# ATSAMC21N17A register map
Registers are 32-bit, access not given, no defined reset value unless marked. A register's access mark holds for its fields unless they carry their own. Addresses are absolute; registers are grouped by the start of their names; [hi:lo] are bit positions.

## TC1
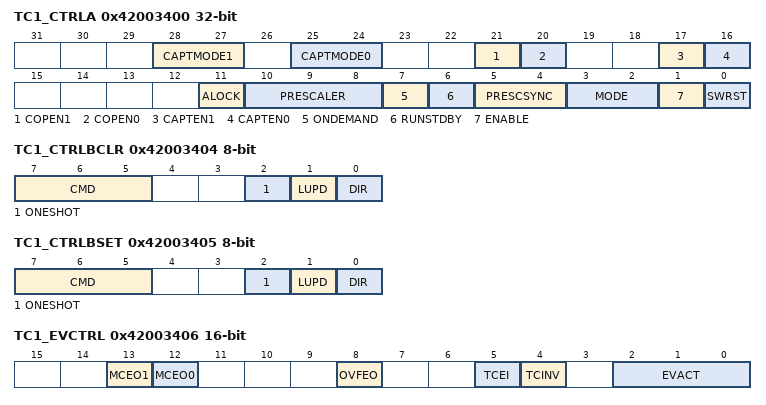
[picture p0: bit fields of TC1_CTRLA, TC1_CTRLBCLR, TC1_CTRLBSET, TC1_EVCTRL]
0x42003400 TC1_CTRLA — Control A
  [28:27] CAPTMODE1, [25:24] CAPTMODE0, [21] COPEN1, [20] COPEN0, [17] CAPTEN1, [16] CAPTEN0, [11] ALOCK, [10:8] PRESCALER, [7] ONDEMAND, [6] RUNSTDBY, [5:4] PRESCSYNC, [3:2] MODE, [1] ENABLE, [0] SWRST
0x42003404 TC1_CTRLBCLR 8-bit — Control B Clear
  [7:5] CMD, [2] ONESHOT, [1] LUPD, [0] DIR
0x42003405 TC1_CTRLBSET 8-bit — Control B Set
  [7:5] CMD, [2] ONESHOT, [1] LUPD, [0] DIR
0x42003406 TC1_EVCTRL 16-bit — Event Control
  [13] MCEO1, [12] MCEO0, [8] OVFEO, [5] TCEI, [4] TCINV, [2:0] EVACT
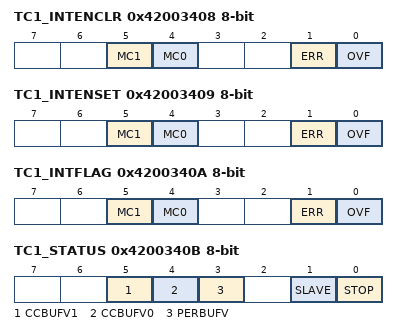
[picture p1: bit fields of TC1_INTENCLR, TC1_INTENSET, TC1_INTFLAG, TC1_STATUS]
0x42003408 TC1_INTENCLR 8-bit — Interrupt Enable Clear
  [5] MC1, [4] MC0, [1] ERR, [0] OVF
0x42003409 TC1_INTENSET 8-bit — Interrupt Enable Set
  [5] MC1, [4] MC0, [1] ERR, [0] OVF
0x4200340A TC1_INTFLAG 8-bit — Interrupt Flag Status and Clear
  [5] MC1, [4] MC0, [1] ERR, [0] OVF
0x4200340B TC1_STATUS 8-bit — Status
  [5] CCBUFV1, [4] CCBUFV0, [3] PERBUFV, [1] SLAVE, [0] STOP
0x4200340C TC1_WAVE 8-bit — Waveform Generation Control
  [1:0] WAVEGEN
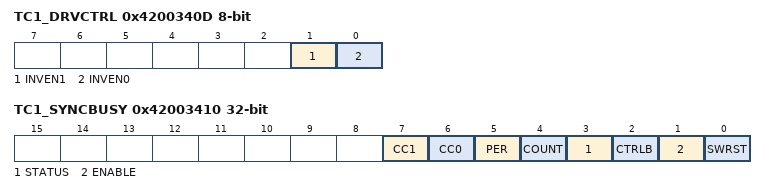
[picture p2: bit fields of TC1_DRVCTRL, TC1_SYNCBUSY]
0x4200340D TC1_DRVCTRL 8-bit — Control C
  [1] INVEN1, [0] INVEN0
0x4200340F TC1_DBGCTRL 8-bit — Debug Control
  [0] DBGRUN
0x42003410 TC1_SYNCBUSY — Synchronization Status
  [7] CC1, [6] CC0, [5] PER, [4] COUNT, [3] STATUS, [2] CTRLB, [1] ENABLE, [0] SWRST
0x42003414 TC1_COUNT_COUNT8 8-bit — COUNT8 Count
  [7:0] COUNT — Counter Value
0x42003414 TC1_COUNT_COUNT16 16-bit — COUNT16 Count
  [15:0] COUNT — Counter Value
0x42003414 TC1_COUNT_COUNT32 — COUNT32 Count
  [31:0] COUNT — Counter Value
0x4200341B TC1_PER_COUNT8 8-bit — COUNT8 Period
  [7:0] PER — Period Value
0x4200341C TC1_CC_COUNT8 8-bit — COUNT8 Compare and Capture
  [7:0] CC — Counter/Compare Value
0x4200341C TC1_CC_COUNT16 16-bit — COUNT16 Compare and Capture
  [15:0] CC — Counter/Compare Value
0x4200341C TC1_CC_COUNT32 — COUNT32 Compare and Capture
  [31:0] CC — Counter/Compare Value
0x4200342F TC1_PERBUF_COUNT8 8-bit — COUNT8 Period Buffer
  [7:0] PERBUF — Period Buffer Value
0x42003430 TC1_CCBUF_COUNT8 8-bit — COUNT8 Compare and Capture Buffer
  [7:0] CCBUF — Counter/Compare Buffer Value
0x42003430 TC1_CCBUF_COUNT16 16-bit — COUNT16 Compare and Capture Buffer
  [15:0] CCBUF — Counter/Compare Buffer Value
0x42003430 TC1_CCBUF_COUNT32 — COUNT32 Compare and Capture Buffer
  [31:0] CCBUF — Counter/Compare Buffer Value

## TC2
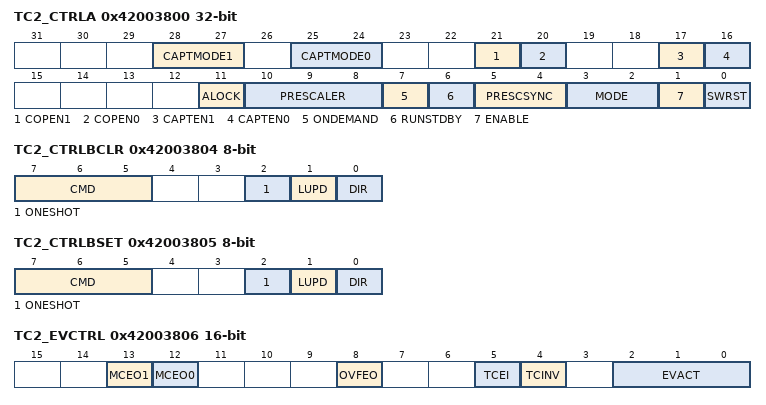
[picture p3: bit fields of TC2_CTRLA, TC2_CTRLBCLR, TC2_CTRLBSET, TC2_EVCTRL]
0x42003800 TC2_CTRLA — Control A
  [28:27] CAPTMODE1, [25:24] CAPTMODE0, [21] COPEN1, [20] COPEN0, [17] CAPTEN1, [16] CAPTEN0, [11] ALOCK, [10:8] PRESCALER, [7] ONDEMAND, [6] RUNSTDBY, [5:4] PRESCSYNC, [3:2] MODE, [1] ENABLE, [0] SWRST
0x42003804 TC2_CTRLBCLR 8-bit — Control B Clear
  [7:5] CMD, [2] ONESHOT, [1] LUPD, [0] DIR
0x42003805 TC2_CTRLBSET 8-bit — Control B Set
  [7:5] CMD, [2] ONESHOT, [1] LUPD, [0] DIR
0x42003806 TC2_EVCTRL 16-bit — Event Control
  [13] MCEO1, [12] MCEO0, [8] OVFEO, [5] TCEI, [4] TCINV, [2:0] EVACT
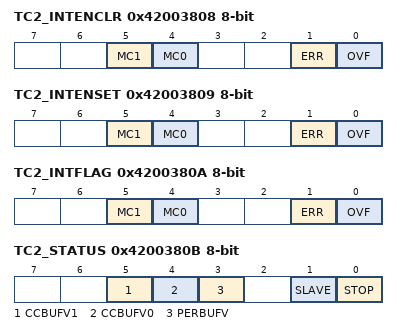
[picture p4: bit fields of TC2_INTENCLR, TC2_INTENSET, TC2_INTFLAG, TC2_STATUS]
0x42003808 TC2_INTENCLR 8-bit — Interrupt Enable Clear
  [5] MC1, [4] MC0, [1] ERR, [0] OVF
0x42003809 TC2_INTENSET 8-bit — Interrupt Enable Set
  [5] MC1, [4] MC0, [1] ERR, [0] OVF
0x4200380A TC2_INTFLAG 8-bit — Interrupt Flag Status and Clear
  [5] MC1, [4] MC0, [1] ERR, [0] OVF
0x4200380B TC2_STATUS 8-bit — Status
  [5] CCBUFV1, [4] CCBUFV0, [3] PERBUFV, [1] SLAVE, [0] STOP
0x4200380C TC2_WAVE 8-bit — Waveform Generation Control
  [1:0] WAVEGEN
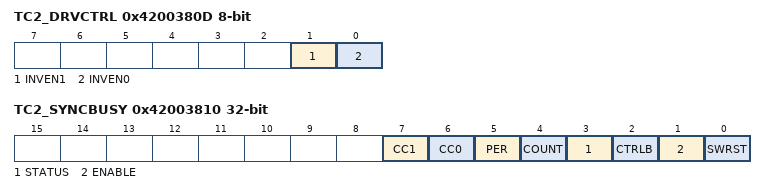
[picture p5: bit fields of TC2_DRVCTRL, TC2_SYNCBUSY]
0x4200380D TC2_DRVCTRL 8-bit — Control C
  [1] INVEN1, [0] INVEN0
0x4200380F TC2_DBGCTRL 8-bit — Debug Control
  [0] DBGRUN
0x42003810 TC2_SYNCBUSY — Synchronization Status
  [7] CC1, [6] CC0, [5] PER, [4] COUNT, [3] STATUS, [2] CTRLB, [1] ENABLE, [0] SWRST
0x42003814 TC2_COUNT_COUNT8 8-bit — COUNT8 Count
  [7:0] COUNT — Counter Value
0x42003814 TC2_COUNT_COUNT16 16-bit — COUNT16 Count
  [15:0] COUNT — Counter Value
0x42003814 TC2_COUNT_COUNT32 — COUNT32 Count
  [31:0] COUNT — Counter Value
0x4200381B TC2_PER_COUNT8 8-bit — COUNT8 Period
  [7:0] PER — Period Value
0x4200381C TC2_CC_COUNT8 8-bit — COUNT8 Compare and Capture
  [7:0] CC — Counter/Compare Value
0x4200381C TC2_CC_COUNT16 16-bit — COUNT16 Compare and Capture
  [15:0] CC — Counter/Compare Value
0x4200381C TC2_CC_COUNT32 — COUNT32 Compare and Capture
  [31:0] CC — Counter/Compare Value
0x4200382F TC2_PERBUF_COUNT8 8-bit — COUNT8 Period Buffer
  [7:0] PERBUF — Period Buffer Value
0x42003830 TC2_CCBUF_COUNT8 8-bit — COUNT8 Compare and Capture Buffer
  [7:0] CCBUF — Counter/Compare Buffer Value
0x42003830 TC2_CCBUF_COUNT16 16-bit — COUNT16 Compare and Capture Buffer
  [15:0] CCBUF — Counter/Compare Buffer Value
0x42003830 TC2_CCBUF_COUNT32 — COUNT32 Compare and Capture Buffer
  [31:0] CCBUF — Counter/Compare Buffer Value
